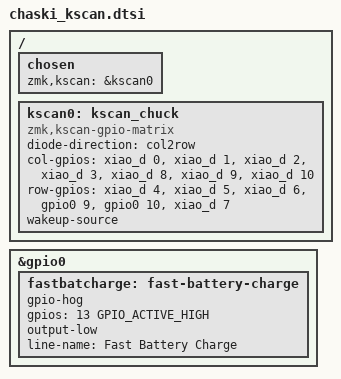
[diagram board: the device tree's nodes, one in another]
/ {
    chosen {
        zmk,kscan = &kscan0;
    };

    kscan0: kscan_chuck {
        compatible = "zmk,kscan-gpio-matrix";

        diode-direction = "col2row";

        col-gpios
            = <&xiao_d 0 GPIO_ACTIVE_HIGH>  // outer, pinky
            , <&xiao_d 1 GPIO_ACTIVE_HIGH>  // ring, middle
            , <&xiao_d 2 GPIO_ACTIVE_HIGH>  // index, inner
            , <&xiao_d 3 GPIO_ACTIVE_HIGH>  // thumbs
            , <&xiao_d 8 GPIO_ACTIVE_HIGH>  // inner, index
            , <&xiao_d 9 GPIO_ACTIVE_HIGH>  // middle, ring
            , <&xiao_d 10 GPIO_ACTIVE_HIGH> // pinky, outer
            ;

        row-gpios
            = <&xiao_d 4 (GPIO_ACTIVE_HIGH | GPIO_PULL_DOWN)> // top
            , <&xiao_d 5 (GPIO_ACTIVE_HIGH | GPIO_PULL_DOWN)> // middle
            , <&xiao_d 6 (GPIO_ACTIVE_HIGH | GPIO_PULL_DOWN)> // bottom
            , <&gpio0 9 (GPIO_ACTIVE_HIGH | GPIO_PULL_DOWN)> // top
            , <&gpio0 10 (GPIO_ACTIVE_HIGH | GPIO_PULL_DOWN)> // middle
            , <&xiao_d 7 (GPIO_ACTIVE_HIGH | GPIO_PULL_DOWN)> // bottom
            ;

        wakeup-source;
    };
};

// For bigger batteries, we want to enable faster charging
&gpio0 {
    fastbatcharge: fast-battery-charge {
        gpio-hog;
        gpios = <13 GPIO_ACTIVE_HIGH>;
        output-low;
        line-name = "Fast Battery Charge";
    };
};

// vim: expandtab softtabstop=4 shiftwidth=4
